# ESP32C5_RADIO register map
Vendor: Espressif; Series: ESP32-C5; File version: 0.1
Registers are 32-bit, read-write, no defined reset value unless marked. A register's access mark holds for its fields unless they carry their own. Offsets are from the block's base; [hi:lo] are bit positions; 'fields as' and 'values as' point back to an identical list.

## PHY_BASEBAND_CONFIG — ESP32-C5 PHY baseband configuration words recovered from complete pinned libphy leaves. Operation-derived fields keep UNKNOWN where no public documentation establishes their electrical meaning.
Base 0x600A0000
0x400 FE_CLOCK_GATE — Project-assigned name. Front-end clock-gate word; libphy[phy_init.o]::phy_open_fe_bb_clk writes 0x1E7.
  [31:0] STATE — Project-assigned name. Complete front-end clock-gate image; individual gate meanings are unknown.
0x408 TABLE_MEMORY_INDEX_SOURCE — Project-assigned name. Word whose bits 31:24 libphy[phy_reg.o]::phy_fe_reg_init replaces with 0xB4.
  [31:24] BASE_INDEX — Project-assigned name. Base index byte.
0x40C FRONT_END_AND_TONE_STOP_CONTROL — Project-assigned name. Word whose bit 2 libphy[phy_reg.o]::phy_fe_reg_init sets.
  [2] BIT_2_OPAQUE — Opaque: meaning not established. Front-end initialization enable; meaning unknown.
0x434 RX_DCO_CONTROL — Project-assigned name. Word whose bits 23:22 phy_iq_swap_set clears.
  [23:22] BITS_22_23_OPAQUE — Opaque: meaning not established. Two-bit calibration control; meaning unknown.
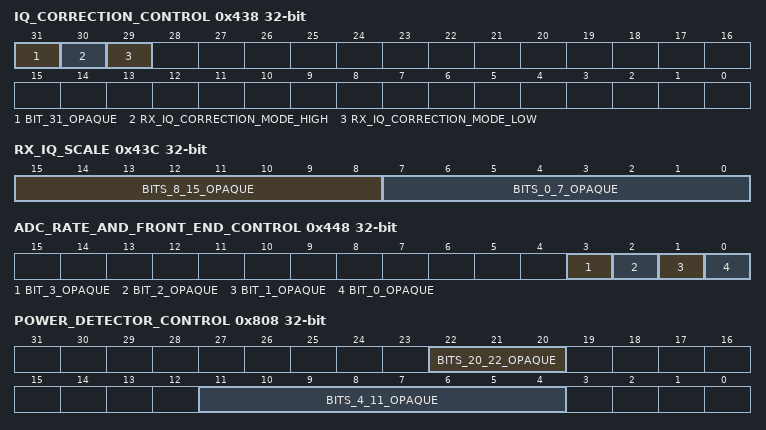
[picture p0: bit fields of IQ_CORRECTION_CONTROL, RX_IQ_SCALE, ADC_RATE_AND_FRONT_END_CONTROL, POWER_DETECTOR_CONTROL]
0x438 IQ_CORRECTION_CONTROL — Project-assigned name. Word whose bits 31:29 libphy[phy_reg.o]::phy_fe_reg_init sets.
  [31] BIT_31_OPAQUE — Opaque: meaning not established. Front-end initialization bit; meaning unknown.
  [30] RX_IQ_CORRECTION_MODE_HIGH — Project-assigned name. RX IQ correction mode, high bit.
  [29] RX_IQ_CORRECTION_MODE_LOW — Project-assigned name. RX IQ correction mode, low bit.
0x43C RX_IQ_SCALE — Project-assigned name. Word whose bits 15:8 and 7:0 libphy[phy_reg.o]::phy_fe_reg_init clears and phy_rxiq_scale_set replaces.
  [15:8] BITS_8_15_OPAQUE — Opaque: meaning not established. High RX IQ scale byte.
  [7:0] BITS_0_7_OPAQUE — Opaque: meaning not established. Low RX IQ scale byte.
0x444 FRONT_END_CLEAR_CONTROL — Project-assigned name. Word whose bit 8 libphy[phy_reg.o]::phy_fe_reg_init clears.
  [8] BIT_8_OPAQUE — Opaque: meaning not established. Front-end initialization clear bit; meaning unknown.
0x448 ADC_RATE_AND_FRONT_END_CONTROL — Project-assigned name. Word whose bits 1:0 libphy[phy_i2c.o]::phy_adc_rate_set replaces with its rate bit and whose bits 3:2 libphy[phy_i2c.o]::phy_dac_rate_set clears.
  [3] BIT_3_OPAQUE — Opaque: meaning not established. Bit 3, cleared by libphy[phy_i2c.o]::phy_dac_rate_set.
  [2] BIT_2_OPAQUE — Opaque: meaning not established. Bit 2, cleared by libphy[phy_i2c.o]::phy_dac_rate_set.
  [1] BIT_1_OPAQUE — Opaque: meaning not established. Bit 1, set to the ADC rate bit by libphy[phy_i2c.o]::phy_adc_rate_set.
  [0] BIT_0_OPAQUE — Opaque: meaning not established. Bit 0, set to the ADC rate bit by libphy[phy_i2c.o]::phy_adc_rate_set.
0x800 FE_BB_CLOCK_CONTROL — Project-assigned name. Word whose bits 1:0 libphy[phy_init.o]::phy_open_fe_bb_clk sets.
  [1:0] BITS_0_1_OPAQUE — Opaque: meaning not established. Two-bit front-end and baseband clock enable; individual meanings unknown.
0x808 POWER_DETECTOR_CONTROL — Project-assigned name. Power-detector control word.
  [22:20] BITS_20_22_OPAQUE — Opaque: meaning not established. Three-bit mode libphy[phy_pwdet.o]::phy_pwdet_reg_init sets to 2 and libphy[phy_pwdet.o]::phy_pwdet_sar2_init to 6.
  [11:4] BITS_4_11_OPAQUE — Opaque: meaning not established. Byte libphy[phy_pwdet.o]::phy_pwdet_reg_init replaces with 0x50.
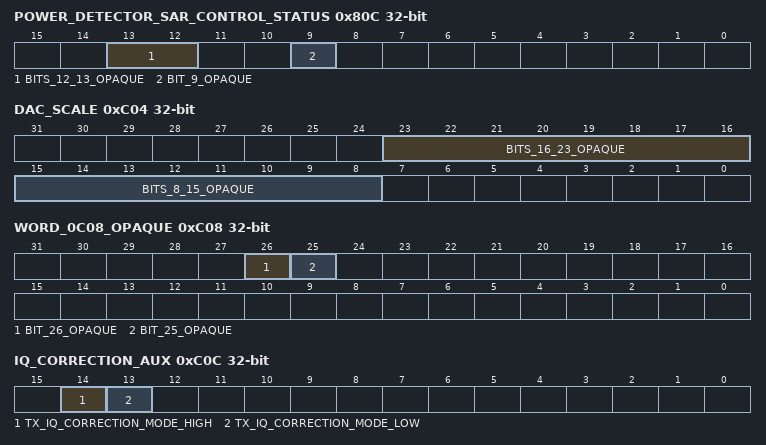
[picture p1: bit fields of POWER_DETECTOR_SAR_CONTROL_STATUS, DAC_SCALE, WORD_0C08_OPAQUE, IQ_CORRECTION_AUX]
0x80C POWER_DETECTOR_SAR_CONTROL_STATUS — Project-assigned name. Power-detector SAR control word.
  [13:12] BITS_12_13_OPAQUE — Opaque: meaning not established. Two bits libphy[phy_pwdet.o]::phy_pwdet_sar2_init sets.
  [9] BIT_9_OPAQUE — Opaque: meaning not established. Bit libphy[phy_pwdet.o]::phy_pwdet_sar2_init clears.
0x810 WORD_0810_OPAQUE — Opaque: meaning not established. Word libphy[phy_pwdet.o]::phy_pwdet_reg_init writes 0x0F0F0FFF.
  [31:0] STATE — Project-assigned name. Complete image; meaning unknown.
0x814 WORD_0814_OPAQUE — Opaque: meaning not established. Word libphy[phy_pwdet.o]::phy_pwdet_reg_init writes 0x00FF0F64.
  fields as WORD_0810_OPAQUE
0x818 POWER_DETECTOR_REFERENCE — Project-assigned name. Word libphy[phy_pwdet.o]::phy_pwdet_reg_init and libphy[phy_pwdet.o]::phy_pwdet_sar2_init write 0xAAAA.
  [31:0] STATE — Project-assigned name. Complete image; the low halfword is the power-detector reference code.
0x870 TX_PA_CONTROL_1 — Project-assigned name. Word whose bits 15:8 libphy[phy_reg.o]::phy_fe_reg_init replaces with 0x96.
  [15:8] PA_ON_BT_DELAY — Project-assigned name. PA-on delay byte.
0x888 WORD_0888_OPAQUE — Opaque: meaning not established. Word whose bit 29 libphy[phy_reg.o]::phy_fe_reg_init sets when phy_param byte 0x2A (set for a channel of at least 3001 MHz) is set and clears otherwise.
  [29] BIT_29_OPAQUE — Opaque: meaning not established. Band-dependent bit that libphy[phy_reg.o]::phy_fe_reg_init sets in the 5 GHz band; meaning unknown.
0x894 WORD_0894_OPAQUE — Opaque: meaning not established. Word whose bit 22 libphy[phy_reg.o]::phy_fe_reg_init sets.
  [22] BIT_22_OPAQUE — Opaque: meaning not established. Front-end initialization enable; meaning unknown.
0xC04 DAC_SCALE — Project-assigned name. Word whose bits 23:16 and then 15:8 phy_dac_scale_set replaces with 0xFF or 0.
  [23:16] BITS_16_23_OPAQUE — Opaque: meaning not established. First DAC scale byte.
  [15:8] BITS_8_15_OPAQUE — Opaque: meaning not established. Second DAC scale byte.
0xC08 WORD_0C08_OPAQUE — Opaque: meaning not established. Word whose bit 25 phy_iq_swap_set clears when phy_param byte 0x2A is set, and whose bits 26:25 it sets otherwise.
  [26] BIT_26_OPAQUE — Opaque: meaning not established. Second bit; meaning unknown.
  [25] BIT_25_OPAQUE — Opaque: meaning not established. First bit; meaning unknown.
0xC0C IQ_CORRECTION_AUX — Project-assigned name. Word whose bits 14:13 libphy[phy_reg.o]::phy_fe_reg_init sets.
  [14] TX_IQ_CORRECTION_MODE_HIGH — Project-assigned name. TX IQ correction mode, high bit.
  [13] TX_IQ_CORRECTION_MODE_LOW — Project-assigned name. TX IQ correction mode, low bit.
0xC20 WORD_0C20_OPAQUE — Opaque: meaning not established. Word whose bits 7:0 libphy[phy_reg.o]::phy_fe_reg_init replaces with 0x57.
  [7:0] BITS_0_7_OPAQUE — Opaque: meaning not established. Low byte; meaning unknown.
0x7920 WORD_7920_OPAQUE — Opaque: meaning not established. Word whose bits 15:12 phy_rxevm_init_cfg clears.
  [15:12] BITS_12_15_OPAQUE — Opaque: meaning not established. Four bits phy_rxevm_init_cfg clears; meaning unknown.
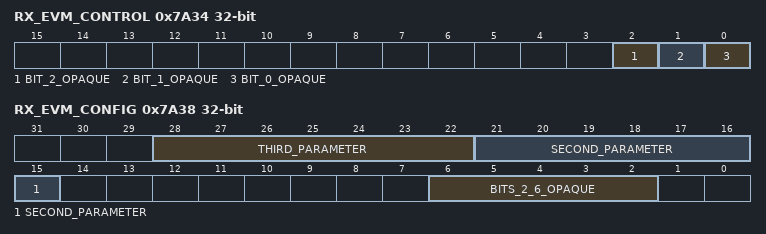
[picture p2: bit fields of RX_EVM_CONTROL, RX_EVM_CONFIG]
0x7A34 RX_EVM_CONTROL — Project-assigned name. RX EVM measurement control.
  [2] BIT_2_OPAQUE — Opaque: meaning not established. Set with bit 0 when phy_rxevm_init_cfg enables the measurement.
  [1] BIT_1_OPAQUE — Opaque: meaning not established. Pulsed by phy_rxevm_reset_mem.
  [0] BIT_0_OPAQUE — Opaque: meaning not established. Set with bit 2 when phy_rxevm_init_cfg enables the measurement.
0x7A38 RX_EVM_CONFIG — Project-assigned name. RX EVM measurement configuration.
  [28:22] THIRD_PARAMETER — Project-assigned name. The third argument of phy_rxevm_init_cfg.
  [21:15] SECOND_PARAMETER — Project-assigned name. The second argument of phy_rxevm_init_cfg.
  [6:2] BITS_2_6_OPAQUE — Opaque: meaning not established. Five bits phy_rxevm_init_cfg sets to 0x18.
0x7C50 RX_EVM_MEMORY_RESET — Project-assigned name. Word whose bit 8 phy_rxevm_reset_mem pulses.
  [8] BIT_8_OPAQUE — Opaque: meaning not established. Pulsed by phy_rxevm_reset_mem.
0x7C80 BB_CLOCK_GATE — Project-assigned name. Baseband clock-gate word; libphy[phy_init.o]::phy_open_fe_bb_clk writes all ones.
  [31:0] STATE — Project-assigned name. Complete baseband clock-gate image; individual gate meanings are unknown.
